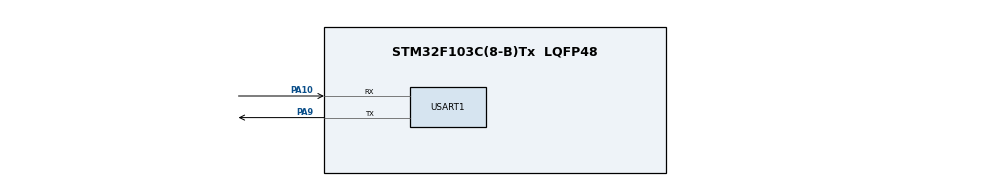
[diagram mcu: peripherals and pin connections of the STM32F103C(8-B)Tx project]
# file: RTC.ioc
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Mcu.Family=STM32F1
Mcu.Name=STM32F103C(8-B)Tx
Mcu.Package=LQFP48
NVIC.PriorityGroup=NVIC_PRIORITYGROUP_4
NVIC.RTC_IRQn=true\:0\:0\:false\:false\:true\:true\:true
PA10.Mode=Asynchronous
PA10.Signal=USART1_RX
PA13.Mode=Trace_Asynchronous_SW
PA13.Signal=SYS_JTMS-SWDIO
PA14.Mode=Trace_Asynchronous_SW
PA14.Signal=SYS_JTCK-SWCLK
PA9.Mode=Asynchronous
PA9.Signal=USART1_TX
PB3.Mode=Trace_Asynchronous_SW
PB3.Signal=SYS_JTDO-TRACESWO
PC14-OSC32_IN.Mode=LSE-External-Oscillator
PC14-OSC32_IN.Signal=RCC_OSC32_IN
PC15-OSC32_OUT.Mode=LSE-External-Oscillator
PC15-OSC32_OUT.Signal=RCC_OSC32_OUT
PD0-OSC_IN.Mode=HSE-External-Oscillator
PD0-OSC_IN.Signal=RCC_OSC_IN
PD1-OSC_OUT.Mode=HSE-External-Oscillator
PD1-OSC_OUT.Signal=RCC_OSC_OUT
ProjectManager.HeapSize=0x200
ProjectManager.StackSize=0x400
ProjectManager.TargetToolchain=Makefile
RCC.AHBFreq_Value=72000000
RCC.APB1CLKDivider=RCC_HCLK_DIV2
RCC.APB1Freq_Value=36000000
RCC.APB1TimFreq_Value=72000000
RCC.APB2Freq_Value=72000000
RCC.APB2TimFreq_Value=72000000
RCC.HCLKFreq_Value=72000000
RCC.PLLMUL=RCC_PLL_MUL9
RCC.PLLSourceVirtual=RCC_PLLSOURCE_HSE
RCC.RTCClockSelection=RCC_RTCCLKSOURCE_LSE
RCC.SYSCLKFreq_VALUE=72000000
RCC.SYSCLKSource=RCC_SYSCLKSOURCE_PLLCLK
RCC.USBFreq_Value=72000000
RTC.AutoPrediv=0
RTC.Date=26
RTC.Format=RTC_FORMAT_BIN
RTC.Hours=23
RTC.Minutes=59
RTC.Month=RTC_MONTH_NOVEMBER
RTC.OutPut=RTC_OUTPUTSOURCE_CALIBCLOCK
RTC.Seconds=59
RTC.WeekDay=RTC_WEEKDAY_THURSDAY
RTC.Year=20
USART1.VirtualMode=VM_ASYNC
VP_RTC_VS_RTC_Activate.Mode=RTC_Enabled
VP_RTC_VS_RTC_Calendar.Mode=RTC_Calendar
board=custom

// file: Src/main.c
/* USER CODE BEGIN Header */
/**
  ******************************************************************************
  * @file           : main.c
  * @brief          : Main program body
  ******************************************************************************
  * @attention
  *
  * <h2><center>&copy; Copyright (c) 2020 STMicroelectronics.
  * All rights reserved.</center></h2>
  *
  * This software component is licensed by ST under BSD 3-Clause license,
  * the "License"; You may not use this file except in compliance with the
  * License. You may obtain a copy of the License at:
  *                        opensource.org/licenses/BSD-3-Clause
  *
  ******************************************************************************
  */
/* USER CODE END Header */
#include "main.h"
#include "rtc.h"
#include "usart.h"
#include "gpio.h"

/* USER CODE BEGIN Includes */
#include <stdio.h>
/* USER CODE END Includes */

void SystemClock_Config(void);

int main(void)
{

  /* MCU Configuration--------------------------------------------------------*/

  /* Reset of all peripherals, Initializes the Flash interface and the Systick. */

  LL_APB2_GRP1_EnableClock(LL_APB2_GRP1_PERIPH_AFIO);
  LL_APB1_GRP1_EnableClock(LL_APB1_GRP1_PERIPH_PWR);

  NVIC_SetPriorityGrouping(NVIC_PRIORITYGROUP_4);

  /* System interrupt init*/

  /** NOJTAG: JTAG-DP Disabled and SW-DP Enabled
  */
  LL_GPIO_AF_Remap_SWJ_NOJTAG();

  /* Configure the system clock */
  SystemClock_Config();

  /* Initialize all configured peripherals */
  MX_GPIO_Init();
  MX_RTC_Init();
  MX_USART1_UART_Init();
  /* USER CODE BEGIN 2 */
  Configure_RTC();
  Configure_RTC_Calendar();
  /* USER CODE END 2 */

  /* Infinite loop */
  while (1)
  {

    /* USER CODE BEGIN 3 */
    Show_RTC_Calendar();
    LL_mDelay(1000);
  }
  /* USER CODE END 3 */
}

void SystemClock_Config(void)
{
  LL_FLASH_SetLatency(LL_FLASH_LATENCY_2);
  while(LL_FLASH_GetLatency()!= LL_FLASH_LATENCY_2)
  {
  }
  LL_RCC_HSE_Enable();

   /* Wait till HSE is ready */
  while(LL_RCC_HSE_IsReady() != 1)
  {

  }
  LL_PWR_EnableBkUpAccess();
  if(LL_RCC_GetRTCClockSource() != LL_RCC_RTC_CLKSOURCE_LSE)
  {
    LL_RCC_ForceBackupDomainReset();
    LL_RCC_ReleaseBackupDomainReset();
  }
  LL_RCC_LSE_Enable();

   /* Wait till LSE is ready */
  while(LL_RCC_LSE_IsReady() != 1)
  {

  }
  if(LL_RCC_GetRTCClockSource() != LL_RCC_RTC_CLKSOURCE_LSE)
  {
    LL_RCC_SetRTCClockSource(LL_RCC_RTC_CLKSOURCE_LSE);
  }
  LL_RCC_EnableRTC();
  LL_RCC_PLL_ConfigDomain_SYS(LL_RCC_PLLSOURCE_HSE_DIV_1, LL_RCC_PLL_MUL_9);
  LL_RCC_PLL_Enable();

   /* Wait till PLL is ready */
  while(LL_RCC_PLL_IsReady() != 1)
  {

  }
  LL_RCC_SetAHBPrescaler(LL_RCC_SYSCLK_DIV_1);
  LL_RCC_SetAPB1Prescaler(LL_RCC_APB1_DIV_2);
  LL_RCC_SetAPB2Prescaler(LL_RCC_APB2_DIV_1);
  LL_RCC_SetSysClkSource(LL_RCC_SYS_CLKSOURCE_PLL);

   /* Wait till System clock is ready */
  while(LL_RCC_GetSysClkSource() != LL_RCC_SYS_CLKSOURCE_STATUS_PLL)
  {

  }
  LL_Init1msTick(72000000);
  LL_SetSystemCoreClock(72000000);
}

void Error_Handler(void)
{
  __disable_irq();
  while (1)
  {
  }
}

/************************ (C) COPYRIGHT STMicroelectronics *****END OF FILE****/
